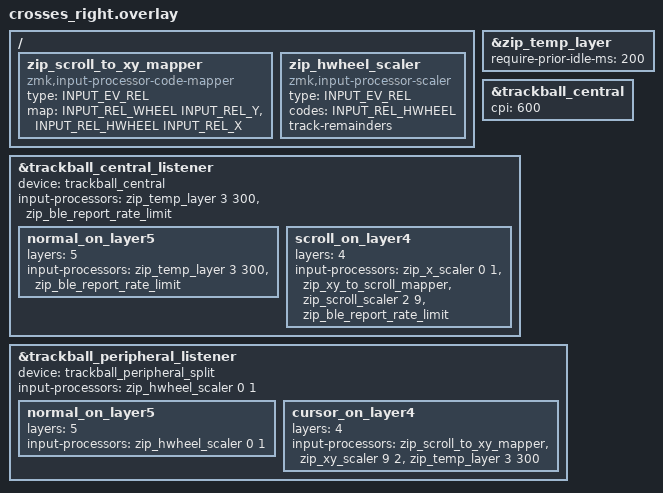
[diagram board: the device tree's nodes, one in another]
// Trackball behaviour. Layer indices (config/crosses.keymap):
//   0 Base, 1 Lower, 2 Raise, 3 Mouse, 4 Extra1, 5 Extra2, 6-7 Extra3-4
//
// Normal:          left = vertical scroll, right = cursor (+ Mouse layer)
// Layer 4 active:  left = cursor (+ Mouse layer), right = vertical scroll
// Layer 5 active:  back to normal even while layer 4 is toggled
//
// Horizontal scrolling is dropped; use Shift + scroll on the host.

#include <zephyr/dt-bindings/input/input-event-codes.h>
#include <dt-bindings/zmk/input_transform.h>

/ {
    // Left ball arrives as WHEEL/HWHEEL (converted on the peripheral).
    // In layer 4 this maps it back to REL_Y/REL_X for cursor movement.
    zip_scroll_to_xy_mapper: zip_scroll_to_xy_mapper {
        compatible = "zmk,input-processor-code-mapper";
        #input-processor-cells = <0>;
        type = <INPUT_EV_REL>;
        map
            = <INPUT_REL_WHEEL INPUT_REL_Y>
            , <INPUT_REL_HWHEEL INPUT_REL_X>
            ;
    };

    // Scales only HWHEEL; used with 0 1 to drop horizontal scroll.
    zip_hwheel_scaler: zip_hwheel_scaler {
        compatible = "zmk,input-processor-scaler";
        #input-processor-cells = <2>;
        type = <INPUT_EV_REL>;
        codes = <INPUT_REL_HWHEEL>;
        track-remainders;
    };
};

// Ignore trackball motion within 200 ms of the last key press, so typing
// vibration does not flip the Mouse layer on.
&zip_temp_layer {
    require-prior-idle-ms = <200>;
};

// Right trackball (local)
&trackball_central {
    cpi = <600>;
};

&trackball_central_listener {
    status = "okay";
    device = <&trackball_central>;

    // Default: move the cursor and temporarily activate the Mouse layer
    // (keymap index 3) for 300 ms after the last movement.
    input-processors
        = <&zip_temp_layer 3 300>
        , <&zip_ble_report_rate_limit>;

    // Layer 5: normal cursor behaviour. Must come before the layer 4 node:
    // the first matching override wins.
    normal_on_layer5 {
        layers = <5>;
        input-processors
            = <&zip_temp_layer 3 300>
            , <&zip_ble_report_rate_limit>;
    };

    // Layer 4: vertical scroll. Natural on Y (already inverted by the
    // sensor orientation). X is zeroed before the mapper.
    // 600 cpi * 2/9 = 133 ticks per inch, same as the left ball's scroll.
    scroll_on_layer4 {
        layers = <4>;
        input-processors
            = <&zip_x_scaler 0 1>
            , <&zip_xy_to_scroll_mapper>
            , <&zip_scroll_scaler 2 9>
            , <&zip_ble_report_rate_limit>;
    };
};

// Left trackball (arrives as scroll events over the split link)
&trackball_peripheral_listener {
    status = "okay";
    device = <&trackball_peripheral_split>;

    // Default: vertical scroll only (drop HWHEEL).
    input-processors = <&zip_hwheel_scaler 0 1>;

    // Layer 5: same as default. Must come before the layer 4 node.
    normal_on_layer5 {
        layers = <5>;
        input-processors = <&zip_hwheel_scaler 0 1>;
    };

    // Layer 4: cursor. Both axes mapped back from scroll codes.
    // Left ball arrives at 400/3 = 133 cpi; * 9/2 = 600 cpi, same as the
    // right ball's cursor.
    cursor_on_layer4 {
        layers = <4>;
        input-processors
            = <&zip_scroll_to_xy_mapper>
            , <&zip_xy_scaler 9 2>
            , <&zip_temp_layer 3 300>;
    };
};
